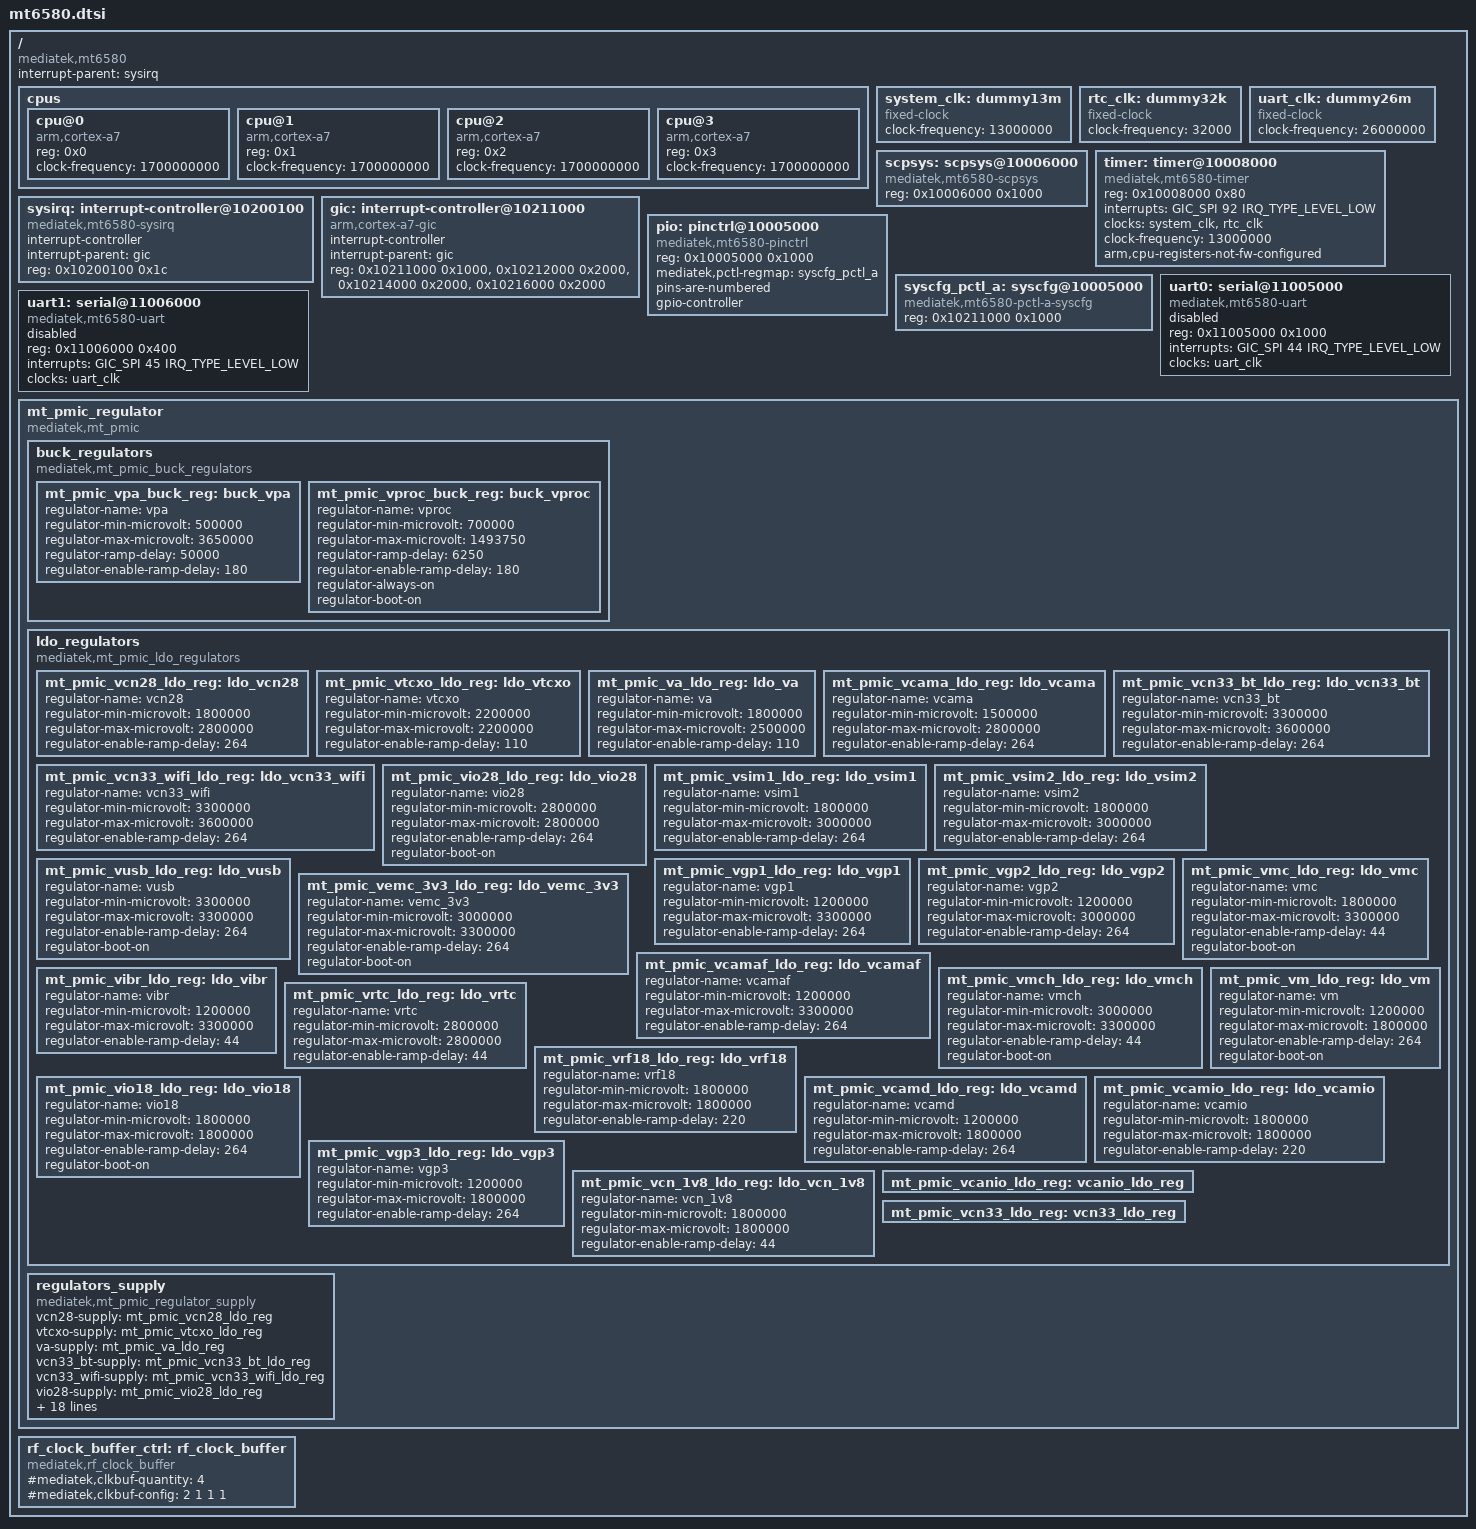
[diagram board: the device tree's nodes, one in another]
// SPDX-License-Identifier: GPL-2.0
/*
 * Copyright (c) 2015 MediaTek Inc.
 * Author: Mars.C <mars.cheng@mediatek.com>
 *
 */

#include <dt-bindings/interrupt-controller/irq.h>
#include <dt-bindings/interrupt-controller/arm-gic.h>
#include <dt-bindings/clock/mt2701-clk.h>
#include <dt-bindings/phy/phy.h>
//#include <dt-bindings/power/mt2701-power.h>
#include "mt6580-pinfunc.h"

/ {
	compatible = "mediatek,mt6580";
	#address-cells = <1>;
	#size-cells = <1>;
	interrupt-parent = <&sysirq>;

	cpus {
		#address-cells = <1>;
		#size-cells = <0>;
//		enable-method = "mediatek,mt6580-smp";

		cpu@0 {
			device_type = "cpu";
			compatible = "arm,cortex-a7";
			reg = <0x0>;
			clock-frequency = <1700000000>;
		};
		cpu@1 {
			device_type = "cpu";
			compatible = "arm,cortex-a7";
			reg = <0x1>;
			clock-frequency = <1700000000>;
		};
		cpu@2 {
			device_type = "cpu";
			compatible = "arm,cortex-a7";
			reg = <0x2>;
			clock-frequency = <1700000000>;
		};
		cpu@3 {
			device_type = "cpu";
			compatible = "arm,cortex-a7";
			reg = <0x3>;
			clock-frequency = <1700000000>;
		};

	};

	system_clk: dummy13m {
		compatible = "fixed-clock";
		clock-frequency = <13000000>;
		#clock-cells = <0>;
	};

	rtc_clk: dummy32k {
		compatible = "fixed-clock";
		clock-frequency = <32000>;
		#clock-cells = <0>;
	};

	uart_clk: dummy26m {
		compatible = "fixed-clock";
		clock-frequency = <26000000>;
		#clock-cells = <0>;
	};

	scpsys: scpsys@10006000 {
		#power-domain-cells = <1>;
		compatible = "mediatek,mt6580-scpsys";
		reg = <0x10006000 0x1000>;
	};

	timer: timer@10008000 {
		compatible = "mediatek,mt6580-timer",
			     "mediatek,mt6577-timer";
		reg = <0x10008000 0x80>;
		interrupts = <GIC_SPI 92 IRQ_TYPE_LEVEL_LOW>;
		clocks = <&system_clk>, <&rtc_clk>;
		clock-names = "system-clk", "rtc-clk";
		clock-frequency = <13000000>;
		arm,cpu-registers-not-fw-configured;
	};

	sysirq: interrupt-controller@10200100 {
		compatible = "mediatek,mt6580-sysirq",
			     "mediatek,mt6577-sysirq";
		interrupt-controller;
		#interrupt-cells = <3>;
		interrupt-parent = <&gic>;
		reg = <0x10200100 0x1c>;
	};

	gic: interrupt-controller@10211000 {
		compatible = "arm,cortex-a7-gic";
		interrupt-controller;
		#interrupt-cells = <3>;
		interrupt-parent = <&gic>;
		reg = <0x10211000 0x1000>,
		      <0x10212000 0x2000>,
		      <0x10214000 0x2000>,
		      <0x10216000 0x2000>;
	};
/*	
	pio: pinctrl@10005000 {
		compatible = "mediatek,mt6580-pinctrl";
		reg = <0x10005000 0 0x1000>;
		mediatek,pctl-regmap = <&syscfg_pctl_a>;
		pins-are-numbered;
		gpio-controller;
		#gpio-cells = <2>;
		interrupt-controller;
		#interrupt-cells = <2>;
		interrupts = <GIC_SPI 113 IRQ_TYPE_LEVEL_HIGH>,
			     <GIC_SPI 114 IRQ_TYPE_LEVEL_HIGH>;
	};

	syscfg_pctl_a: syscfg@10005000 {
		compatible = "mediatek,mt6580-pctl-a-syscfg", "syscon";
		reg = <0x10211000 0x1000>;
	};
*/

	pio: pinctrl@10005000 {
		compatible = "mediatek,mt6580-pinctrl";
		reg = <0x10005000 0x1000>;
		mediatek,pctl-regmap = <&syscfg_pctl_a>;
		pins-are-numbered;
		gpio-controller;
		#gpio-cells = <2>;
//		pinctrl-use-default;
//		pinctrl-names = "default";
//		pinctrl-0 = <>;
	};

	syscfg_pctl_a: syscfg@10005000 {
		compatible = "mediatek,mt6580-pctl-a-syscfg", "syscon";
		reg = <0x10211000 0x1000>;
	};

	uart0: serial@11005000 {
		compatible = "mediatek,mt6580-uart",
			     "mediatek,mt6577-uart";
		reg = <0x11005000 0x1000>;
		interrupts = <GIC_SPI 44 IRQ_TYPE_LEVEL_LOW>;
		clocks = <&uart_clk>;
		status = "disabled";
	};

	uart1: serial@11006000 {
		compatible = "mediatek,mt6580-uart",
			     "mediatek,mt6577-uart";
		reg = <0x11006000 0x400>;
		interrupts = <GIC_SPI 45 IRQ_TYPE_LEVEL_LOW>;
		clocks = <&uart_clk>;
		status = "disabled";
	};
/*
	usb2: usb@11100000 {
		compatible = "mediatek,mt6580-musb",
			     "mediatek,mtk-musb";
		reg = <0 0x11100000 0 0x1000>;
		interrupts = <GIC_SPI 32 IRQ_TYPE_LEVEL_LOW>;
		interrupt-names = "mc";
		phys = <&u2port2 PHY_TYPE_USB2>;
		dr_mode = "otg";
		clocks = <&pericfg CLK_PERI_USB0>,
			 <&pericfg CLK_PERI_USB0_MCU>,
			 <&pericfg CLK_PERI_USB_SLV>;
		clock-names = "main","mcu","univpll";
		power-domains = <&scpsys MT2701_POWER_DOMAIN_IFR_MSC>;
		status = "disabled";
	};

	u2phy0: usb-phy@0xe0420000 {
		compatible = "mediatek,generic-tphy-v1";
		reg = <0 0xe0420000 0 0x0800>;
		#address-cells = <2>;
		#size-cells = <2>;
		ranges;
		status = "okay";

		u2port2: usb-phy@0xe0440000 {
			reg = <0 0xe0440000 0 0x0100>;
			clocks = <&topckgen CLK_TOP_USB_PHY48M>;
			clock-names = "ref";
			#phy-cells = <1>;
			status = "okay";
		};
	};
*/
	mt_pmic_regulator {
		compatible = "mediatek,mt_pmic";
		buck_regulators {
			compatible = "mediatek,mt_pmic_buck_regulators";
			mt_pmic_vpa_buck_reg: buck_vpa {
				regulator-name = "vpa";
				regulator-min-microvolt = <500000>;
				regulator-max-microvolt = <3650000>;
				regulator-ramp-delay = <50000>;
				regulator-enable-ramp-delay = <180>;
			};
			mt_pmic_vproc_buck_reg: buck_vproc {
				regulator-name = "vproc";
				regulator-min-microvolt = <700000>;
				regulator-max-microvolt = <1493750>;
				regulator-ramp-delay = <6250>;
				regulator-enable-ramp-delay = <180>;
				regulator-always-on;
				regulator-boot-on;
			};
		};	/* End of buck_regulators */
		ldo_regulators {
			compatible = "mediatek,mt_pmic_ldo_regulators";
			mt_pmic_vcn28_ldo_reg: ldo_vcn28 {
				regulator-name = "vcn28";
				regulator-min-microvolt = <1800000>;
				regulator-max-microvolt = <2800000>;
				regulator-enable-ramp-delay = <264>;
			};
			mt_pmic_vtcxo_ldo_reg: ldo_vtcxo {
				regulator-name = "vtcxo";
				regulator-min-microvolt = <2200000>;
				regulator-max-microvolt = <2200000>;
				regulator-enable-ramp-delay = <110>;
			};
			mt_pmic_va_ldo_reg: ldo_va {
				regulator-name = "va";
				regulator-min-microvolt = <1800000>;
				regulator-max-microvolt = <2500000>;
				regulator-enable-ramp-delay = <110>;
			};
			mt_pmic_vcama_ldo_reg: ldo_vcama {
				regulator-name = "vcama";
				regulator-min-microvolt = <1500000>;
				regulator-max-microvolt = <2800000>;
				regulator-enable-ramp-delay = <264>;
			};
			mt_pmic_vcn33_bt_ldo_reg: ldo_vcn33_bt {
				regulator-name = "vcn33_bt";
				regulator-min-microvolt = <3300000>;
				regulator-max-microvolt = <3600000>;
				regulator-enable-ramp-delay = <264>;
			};
			mt_pmic_vcn33_wifi_ldo_reg: ldo_vcn33_wifi {
				regulator-name = "vcn33_wifi";
				regulator-min-microvolt = <3300000>;
				regulator-max-microvolt = <3600000>;
				regulator-enable-ramp-delay = <264>;
			};
			mt_pmic_vio28_ldo_reg: ldo_vio28 {
				regulator-name = "vio28";
				regulator-min-microvolt = <2800000>;
				regulator-max-microvolt = <2800000>;
				regulator-enable-ramp-delay = <264>;
				regulator-boot-on;
			};
			mt_pmic_vsim1_ldo_reg: ldo_vsim1 {
				regulator-name = "vsim1";
				regulator-min-microvolt = <1800000>;
				regulator-max-microvolt = <3000000>;
				regulator-enable-ramp-delay = <264>;
			};
			mt_pmic_vsim2_ldo_reg: ldo_vsim2 {
				regulator-name = "vsim2";
				regulator-min-microvolt = <1800000>;
				regulator-max-microvolt = <3000000>;
				regulator-enable-ramp-delay = <264>;
			};
			mt_pmic_vusb_ldo_reg: ldo_vusb {
				regulator-name = "vusb";
				regulator-min-microvolt = <3300000>;
				regulator-max-microvolt = <3300000>;
				regulator-enable-ramp-delay = <264>;
				regulator-boot-on;
			};
			mt_pmic_vgp1_ldo_reg: ldo_vgp1 {
				regulator-name = "vgp1";
				regulator-min-microvolt = <1200000>;
				regulator-max-microvolt = <3300000>;
				regulator-enable-ramp-delay = <264>;
			};
			mt_pmic_vgp2_ldo_reg: ldo_vgp2 {
				regulator-name = "vgp2";
				regulator-min-microvolt = <1200000>;
				regulator-max-microvolt = <3000000>;
				regulator-enable-ramp-delay = <264>;
			};
			mt_pmic_vemc_3v3_ldo_reg: ldo_vemc_3v3 {
				regulator-name = "vemc_3v3";
				regulator-min-microvolt = <3000000>;
				regulator-max-microvolt = <3300000>;
				regulator-enable-ramp-delay = <264>;
				regulator-boot-on;
			};
			mt_pmic_vcamaf_ldo_reg: ldo_vcamaf {
				regulator-name = "vcamaf";
				regulator-min-microvolt = <1200000>;
				regulator-max-microvolt = <3300000>;
				regulator-enable-ramp-delay = <264>;
			};
			mt_pmic_vmc_ldo_reg: ldo_vmc {
				regulator-name = "vmc";
				regulator-min-microvolt = <1800000>;
				regulator-max-microvolt = <3300000>;
				regulator-enable-ramp-delay = <44>;
				regulator-boot-on;
			};
			mt_pmic_vmch_ldo_reg: ldo_vmch {
				regulator-name = "vmch";
				regulator-min-microvolt = <3000000>;
				regulator-max-microvolt = <3300000>;
				regulator-enable-ramp-delay = <44>;
				regulator-boot-on;
			};
			mt_pmic_vibr_ldo_reg: ldo_vibr {
				regulator-name = "vibr";
				regulator-min-microvolt = <1200000>;
				regulator-max-microvolt = <3300000>;
				regulator-enable-ramp-delay = <44>;
			};
			mt_pmic_vrtc_ldo_reg: ldo_vrtc {
				regulator-name = "vrtc";
				regulator-min-microvolt = <2800000>;
				regulator-max-microvolt = <2800000>;
				regulator-enable-ramp-delay = <44>;
			};
			mt_pmic_vm_ldo_reg: ldo_vm {
				regulator-name = "vm";
				regulator-min-microvolt = <1200000>;
				regulator-max-microvolt = <1800000>;
				regulator-enable-ramp-delay = <264>;
				regulator-boot-on;
			};
			mt_pmic_vrf18_ldo_reg: ldo_vrf18 {
				regulator-name = "vrf18";
				regulator-min-microvolt = <1800000>;
				regulator-max-microvolt = <1800000>;
				regulator-enable-ramp-delay = <220>;
			};
			mt_pmic_vio18_ldo_reg: ldo_vio18 {
				regulator-name = "vio18";
				regulator-min-microvolt = <1800000>;
				regulator-max-microvolt = <1800000>;
				regulator-enable-ramp-delay = <264>;
				regulator-boot-on;
			};
			mt_pmic_vcamd_ldo_reg: ldo_vcamd {
				regulator-name = "vcamd";
				regulator-min-microvolt = <1200000>;
				regulator-max-microvolt = <1800000>;
				regulator-enable-ramp-delay = <264>;
			};
			mt_pmic_vcamio_ldo_reg: ldo_vcamio {
				regulator-name = "vcamio";
				regulator-min-microvolt = <1800000>;
				regulator-max-microvolt = <1800000>;
				regulator-enable-ramp-delay = <220>;
			};
			mt_pmic_vgp3_ldo_reg: ldo_vgp3 {
				regulator-name = "vgp3";
				regulator-min-microvolt = <1200000>;
				regulator-max-microvolt = <1800000>;
				regulator-enable-ramp-delay = <264>;
			};
			mt_pmic_vcn_1v8_ldo_reg: ldo_vcn_1v8 {
			regulator-name = "vcn_1v8";
				regulator-min-microvolt = <1800000>;
				regulator-max-microvolt = <1800000>;
				regulator-enable-ramp-delay = <44>;
			};

			mt_pmic_vcanio_ldo_reg:vcanio_ldo_reg {
			};
			mt_pmic_vcn33_ldo_reg:vcn33_ldo_reg {
			};
		};/* End of ldo_regulators */
		regulators_supply {
			compatible = "mediatek,mt_pmic_regulator_supply";
			vcn28-supply = <&mt_pmic_vcn28_ldo_reg>;
			vtcxo-supply = <&mt_pmic_vtcxo_ldo_reg>;
			va-supply = <&mt_pmic_va_ldo_reg>;
			vcn33_bt-supply = <&mt_pmic_vcn33_bt_ldo_reg>;
			vcn33_wifi-supply = <&mt_pmic_vcn33_wifi_ldo_reg>;
			vio28-supply = <&mt_pmic_vio28_ldo_reg>;
			vsim1-supply = <&mt_pmic_vsim1_ldo_reg>;
			vsim2-supply = <&mt_pmic_vsim2_ldo_reg>;
			vusb-supply = <&mt_pmic_vusb_ldo_reg>;
			vgp1-supply = <&mt_pmic_vgp1_ldo_reg>;
			vgp2-supply = <&mt_pmic_vgp2_ldo_reg>;
			vemc_3v3-supply = <&mt_pmic_vemc_3v3_ldo_reg>;
			vcamaf-supply = <&mt_pmic_vcamaf_ldo_reg>;
			vmc-supply = <&mt_pmic_vmc_ldo_reg>;
			vmch-supply = <&mt_pmic_vmch_ldo_reg>;
			vibr-supply = <&mt_pmic_vibr_ldo_reg>;
			vrtc-supply = <&mt_pmic_vrtc_ldo_reg>;
			vm-supply = <&mt_pmic_vm_ldo_reg>;
			vrf18-supply = <&mt_pmic_vrf18_ldo_reg>;
			vio18-supply = <&mt_pmic_vio18_ldo_reg>;
			vcamd-supply = <&mt_pmic_vcamd_ldo_reg>;
			vcamio-supply = <&mt_pmic_vcamio_ldo_reg>;
			vgp3-supply = <&mt_pmic_vgp3_ldo_reg>;
			vcn_1v8-supply = <&mt_pmic_vcn_1v8_ldo_reg>;
		};/* End of regulators_supply */
	};/* End of mt_pmic_regulator */

	rf_clock_buffer_ctrl:rf_clock_buffer {
		compatible = "mediatek,rf_clock_buffer";
		#mediatek,clkbuf-quantity = <4>;
		#mediatek,clkbuf-config = <2 1 1 1>;
	};

};
